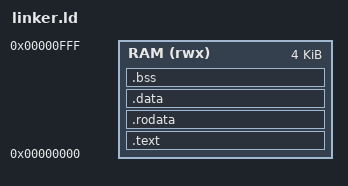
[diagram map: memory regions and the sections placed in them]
ENTRY(_start)

MEMORY
{
    RAM (rwx) : ORIGIN = 0x00000000, LENGTH = 4K
}

SECTIONS
{
    .text :
    {
        KEEP(*(.text.init))
        *(.text*)
    } > RAM

    .rodata :
    {
        *(.rodata*)
    } > RAM

    .data :
    {
        *(.data*)
    } > RAM

    .bss (NOLOAD) :
    {
        __bss_start = .;
        *(.bss*)
        *(COMMON)
        __bss_end = .;
    } > RAM

    . = ALIGN(4);
    __image_end = .;
    __stack_top = ORIGIN(RAM) + LENGTH(RAM);

    ASSERT(__image_end <= __stack_top, "program does not fit in emulator memory")
}
